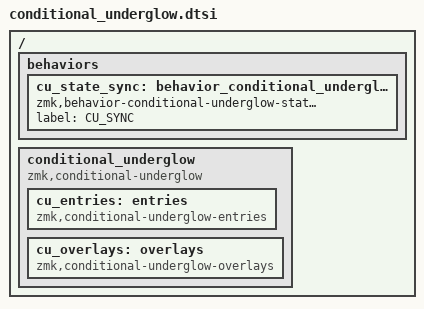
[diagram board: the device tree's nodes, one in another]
/* Short alias for "no LED on this half" in the parent `map` array. Two
 * underscores aligns visually with 1-2 digit key-position indices. */
#define __ 0xFFFF

/ {
    behaviors {
        /* Internal: state sync from central to peripheral. Don't reference
         * in keymaps. Forwarding to peripheral is enabled by the
         * `.locality = BEHAVIOR_LOCALITY_GLOBAL` field in the driver API
         * struct (DT `locality` property is unread by ZMK). */
        cu_state_sync: behavior_conditional_underglow_state_sync {
            compatible = "zmk,behavior-conditional-underglow-state-sync";
            #binding-cells = <1>;
            /* Short label: ZMK split RUN_BEHAVIOR payload truncates the
             * behavior name to a small fixed buffer. Full node name
             * ("behavior_conditional_underglow_state_sync") is 41 chars and
             * gets cut → device_get_binding fails on peripheral with -EINVAL.
             * DEVICE_DT_NAME() prefers the label property when present. */
            label = "CU_SYNC";
        };
    };

    conditional_underglow: conditional_underglow {
        compatible = "zmk,conditional-underglow";

        cu_entries: entries {
            compatible = "zmk,conditional-underglow-entries";
        };

        cu_overlays: overlays {
            compatible = "zmk,conditional-underglow-overlays";
        };
    };
};
